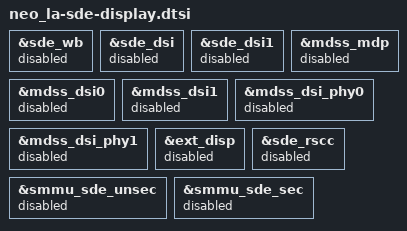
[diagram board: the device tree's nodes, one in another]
#include "neo-sde-display.dtsi"

&sde_wb {
        status = "disabled";
};

&sde_dsi {
        status = "disabled";
};

&sde_dsi1 {
        status = "disabled";
};

&mdss_mdp {
        status = "disabled";
};

&mdss_dsi0 {
        status = "disabled";
};

&mdss_dsi1 {
        status = "disabled";
};

&mdss_dsi_phy0 {
        status = "disabled";
};

&mdss_dsi_phy1 {
        status = "disabled";
};

&ext_disp {
        status = "disabled";
};

&sde_rscc {
        status = "disabled";
};

&smmu_sde_unsec {
        status = "disabled";
};

&smmu_sde_sec {
        status = "disabled";
};
